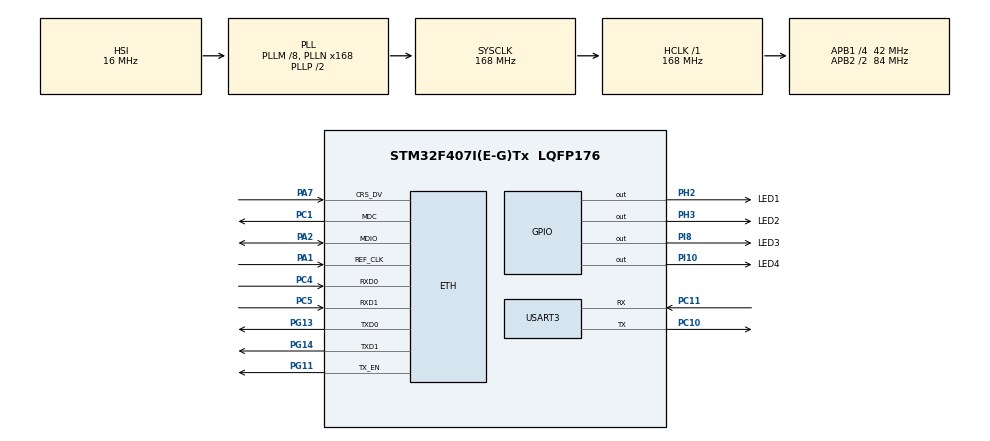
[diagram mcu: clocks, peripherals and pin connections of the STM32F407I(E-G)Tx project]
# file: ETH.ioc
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ETH.MediaInterface=ETH_MEDIA_INTERFACE_RMII
LWIP.LWIP_NETIF_LINK_CALLBACK=1
LWIP.TCP_QUEUE_OOSEQ=0
LWIP.Version=v1.5.0_RC0_20160211_Cube
Mcu.Family=STM32F4
Mcu.Name=STM32F407I(E-G)Tx
Mcu.Package=LQFP176
NVIC.ETH_IRQn=true\:0\:0\:false\:false\:true
NVIC.PriorityGroup=NVIC_PRIORITYGROUP_4
PA1.Mode=RMII
PA1.Signal=ETH_REF_CLK
PA2.Mode=RMII
PA2.Signal=ETH_MDIO
PA7.Mode=RMII
PA7.Signal=ETH_CRS_DV
PC1.Mode=RMII
PC1.Signal=ETH_MDC
PC10.Mode=Asynchronous
PC10.Signal=USART3_TX
PC11.Mode=Asynchronous
PC11.Signal=USART3_RX
PC4.Mode=RMII
PC4.Signal=ETH_RXD0
PC5.Mode=RMII
PC5.Signal=ETH_RXD1
PG11.Mode=RMII
PG11.Signal=ETH_TX_EN
PG13.Mode=RMII
PG13.Signal=ETH_TXD0
PG14.Mode=RMII
PG14.Signal=ETH_TXD1
PH0-OSC_IN.Mode=HSE-External-Oscillator
PH0-OSC_IN.Signal=RCC_OSC_IN
PH1-OSC_OUT.Mode=HSE-External-Oscillator
PH1-OSC_OUT.Signal=RCC_OSC_OUT
PH2.GPIO_Label=LED1
PH2.Signal=GPIO_Output
PH3.GPIO_Label=LED2
PH3.Signal=GPIO_Output
PI10.GPIO_Label=LED4
PI10.Signal=GPIO_Output
PI8-\ ANTI\ TAMP2.GPIO_Label=LED3
PI8-\ ANTI\ TAMP2.Signal=GPIO_Output
ProjectManager.HeapSize=0x200
ProjectManager.StackSize=0x400
ProjectManager.TargetToolchain=MDK-ARM V5
RCC.48MHZClocksFreq_Value=84000000
RCC.AHBFreq_Value=168000000
RCC.APB1CLKDivider=RCC_HCLK_DIV4
RCC.APB1Freq_Value=42000000
RCC.APB1TimFreq_Value=84000000
RCC.APB2CLKDivider=RCC_HCLK_DIV2
RCC.APB2Freq_Value=84000000
RCC.APB2TimFreq_Value=168000000
RCC.CortexFreq_Value=168000000
RCC.HCLKFreq_Value=168000000
RCC.HSE_VALUE=8000000
RCC.HSI_VALUE=16000000
RCC.LSE_VALUE=32768
RCC.PLLM=8
RCC.PLLN=168
RCC.SYSCLKFreq_VALUE=168000000
RCC.SYSCLKSource=RCC_SYSCLKSOURCE_PLLCLK
RCC.VCOOutputFreq_Value=336000000
VP_LWIP_VS_Enabled.Mode=Enabled
board=ETH

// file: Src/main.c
/**
  ******************************************************************************
  * File Name          : main.c
  * Description        : Main program body
  ******************************************************************************
  *
  * Copyright (c) 2017 STMicroelectronics International N.V.
  * All rights reserved.
  *
  * Redistribution and use in source and binary forms, with or without
  * modification, are permitted, provided that the following conditions are met:
  *
  * 1. Redistribution of source code must retain the above copyright notice,
  *    this list of conditions and the following disclaimer.
  * 2. Redistributions in binary form must reproduce the above copyright notice,
  *    this list of conditions and the following disclaimer in the documentation
  *    and/or other materials provided with the distribution.
  * 3. Neither the name of STMicroelectronics nor the names of other
  *    contributors to this software may be used to endorse or promote products
  *    derived from this software without specific written permission.
  * 4. This software, including modifications and/or derivative works of this
  *    software, must execute solely and exclusively on microcontroller or
  *    microprocessor devices manufactured by or for STMicroelectronics.
  * 5. Redistribution and use of this software other than as permitted under
  *    this license is void and will automatically terminate your rights under
  *    this license.
  *
  * THIS SOFTWARE IS PROVIDED BY STMICROELECTRONICS AND CONTRIBUTORS "AS IS"
  * AND ANY EXPRESS, IMPLIED OR STATUTORY WARRANTIES, INCLUDING, BUT NOT
  * LIMITED TO, THE IMPLIED WARRANTIES OF MERCHANTABILITY, FITNESS FOR A
  * PARTICULAR PURPOSE AND NON-INFRINGEMENT OF THIRD PARTY INTELLECTUAL PROPERTY
  * RIGHTS ARE DISCLAIMED TO THE FULLEST EXTENT PERMITTED BY LAW. IN NO EVENT
  * SHALL STMICROELECTRONICS OR CONTRIBUTORS BE LIABLE FOR ANY DIRECT, INDIRECT,
  * INCIDENTAL, SPECIAL, EXEMPLARY, OR CONSEQUENTIAL DAMAGES (INCLUDING, BUT NOT
  * LIMITED TO, PROCUREMENT OF SUBSTITUTE GOODS OR SERVICES; LOSS OF USE, DATA,
  * OR PROFITS; OR BUSINESS INTERRUPTION) HOWEVER CAUSED AND ON ANY THEORY OF
  * LIABILITY, WHETHER IN CONTRACT, STRICT LIABILITY, OR TORT (INCLUDING
  * NEGLIGENCE OR OTHERWISE) ARISING IN ANY WAY OUT OF THE USE OF THIS SOFTWARE,
  * EVEN IF ADVISED OF THE POSSIBILITY OF SUCH DAMAGE.
  *
  ******************************************************************************
  */
#include "main.h"
#include "stm32f4xx_hal.h"
#include "lwip.h"
#include "usart.h"
#include "gpio.h"

/* USER CODE BEGIN Includes */
#include "app_ethernet.h"
#include "httpd.h"
/* USER CODE END Includes */

/* USER CODE BEGIN PV */
/* Private variables ---------------------------------------------------------*/
extern struct netif gnetif;
/* USER CODE END PV */

void SystemClock_Config(void);
void Error_Handler(void);

/* USER CODE BEGIN PFP */
/* Private function prototypes -----------------------------------------------*/

/* USER CODE END PFP */

int main(void)
{

  /* MCU Configuration----------------------------------------------------------*/

  /* Reset of all peripherals, Initializes the Flash interface and the Systick. */
  HAL_Init();

  /* Configure the system clock */
  SystemClock_Config();

  /* Initialize all configured peripherals */
  MX_GPIO_Init();
  MX_USART3_UART_Init();
  MX_LWIP_Init();

  /* USER CODE BEGIN 2 */
  /* Show Header and Footer texts */
  UsrLog("Webserver Application Raw API\r\n");
  UsrLog("Ethernet Initialization ...\r\n");

	/* Http webserver Init */
  httpd_init();

  /* Notify user about the netwoek interface config */
  User_notification(&gnetif);
  /* USER CODE END 2 */

  /* Infinite loop */
  while (1)
  {

  /* USER CODE BEGIN 3 */
    MX_LWIP_Process();
#ifdef USE_DHCP
		/* handle periodic timers for DHCP */
    DHCP_Periodic_Handle(&gnetif);
#endif

  }
  /* USER CODE END 3 */

}

/** System Clock Configuration
*/
void SystemClock_Config(void)
{

  RCC_OscInitTypeDef RCC_OscInitStruct;
  RCC_ClkInitTypeDef RCC_ClkInitStruct;

    /**Configure the main internal regulator output voltage
    */
  __HAL_RCC_PWR_CLK_ENABLE();

  __HAL_PWR_VOLTAGESCALING_CONFIG(PWR_REGULATOR_VOLTAGE_SCALE1);

    /**Initializes the CPU, AHB and APB busses clocks
    */
  RCC_OscInitStruct.OscillatorType = RCC_OSCILLATORTYPE_HSI;
  RCC_OscInitStruct.HSIState = RCC_HSI_ON;
  RCC_OscInitStruct.HSICalibrationValue = 16;
  RCC_OscInitStruct.PLL.PLLState = RCC_PLL_ON;
  RCC_OscInitStruct.PLL.PLLSource = RCC_PLLSOURCE_HSI;
  RCC_OscInitStruct.PLL.PLLM = 8;
  RCC_OscInitStruct.PLL.PLLN = 168;
  RCC_OscInitStruct.PLL.PLLP = RCC_PLLP_DIV2;
  RCC_OscInitStruct.PLL.PLLQ = 4;
  if (HAL_RCC_OscConfig(&RCC_OscInitStruct) != HAL_OK)
  {
    Error_Handler();
  }

    /**Initializes the CPU, AHB and APB busses clocks
    */
  RCC_ClkInitStruct.ClockType = RCC_CLOCKTYPE_HCLK|RCC_CLOCKTYPE_SYSCLK
                              |RCC_CLOCKTYPE_PCLK1|RCC_CLOCKTYPE_PCLK2;
  RCC_ClkInitStruct.SYSCLKSource = RCC_SYSCLKSOURCE_PLLCLK;
  RCC_ClkInitStruct.AHBCLKDivider = RCC_SYSCLK_DIV1;
  RCC_ClkInitStruct.APB1CLKDivider = RCC_HCLK_DIV4;
  RCC_ClkInitStruct.APB2CLKDivider = RCC_HCLK_DIV2;

  if (HAL_RCC_ClockConfig(&RCC_ClkInitStruct, FLASH_LATENCY_5) != HAL_OK)
  {
    Error_Handler();
  }

    /**Configure the Systick interrupt time
    */
  HAL_SYSTICK_Config(HAL_RCC_GetHCLKFreq()/1000);

    /**Configure the Systick
    */
  HAL_SYSTICK_CLKSourceConfig(SYSTICK_CLKSOURCE_HCLK);

  /* SysTick_IRQn interrupt configuration */
  HAL_NVIC_SetPriority(SysTick_IRQn, 0, 0);
}

void Error_Handler(void)
{
  while(1)
  {
  }
}

/************************ (C) COPYRIGHT STMicroelectronics *****END OF FILE****/
